BO_ 1620 CAN_Message_1: 8 BCM
 SG_ SIG_12_05 : 55|16@0+ (0.001,0) [0|5] "V"  ECU,BCM
 SG_ SIG_05 : 39|16@0+ (0.001,0) [0|5] "V"  ECU,BCM
 SG_ SIG_05 : 23|16@0+ (0.001,0) [0|5] "V"  ECU,BCM
 SG_ SIG_05 : 7|16@0+ (0.001,0) [0|5] "V"  ECU,BCM

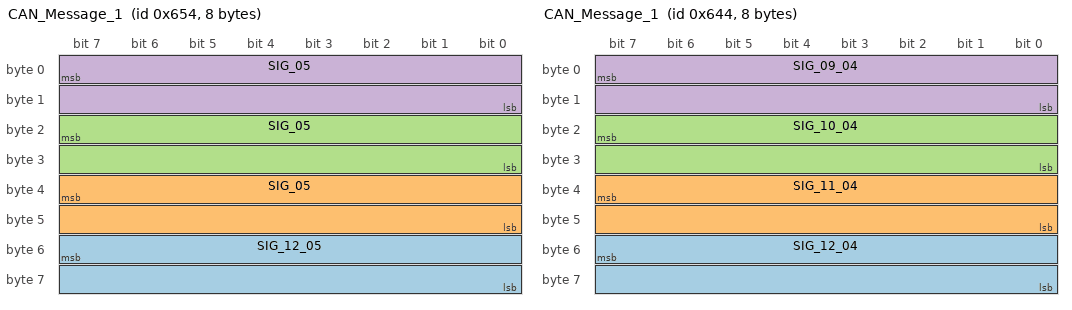
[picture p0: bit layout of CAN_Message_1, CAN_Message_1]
BO_ 1604 CAN_Message_1: 8 BCM
 SG_ SIG_12_04 : 55|16@0+ (0.001,0) [0|5] "V"  ECU,BCM
 SG_ SIG_11_04 : 39|16@0+ (0.001,0) [0|5] "V"  ECU,BCM
 SG_ SIG_10_04 : 23|16@0+ (0.001,0) [0|5] "V"  ECU,BCM
 SG_ SIG_09_04 : 7|16@0+ (0.001,0) [0|5] "V"  ECU,BCM

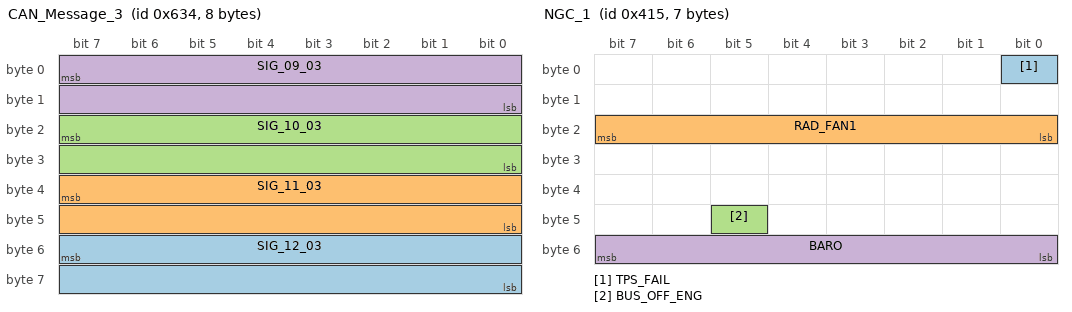
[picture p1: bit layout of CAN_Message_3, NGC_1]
BO_ 1588 CAN_Message_3: 8 BCM
 SG_ SIG_12_03 : 55|16@0+ (0.001,0) [0|5] "V"  ECU,BCM
 SG_ SIG_11_03 : 39|16@0+ (0.001,0) [0|5] "V"  ECU,BCM
 SG_ SIG_10_03 : 23|16@0+ (0.001,0) [0|5] "V"  ECU,BCM
 SG_ SIG_09_03 : 7|16@0+ (0.001,0) [0|5] "V"  ECU,BCM

BO_ 1045 NGC_1: 7 ENG_PHEV
 SG_ TPS_FAIL : 0|1@1+ (1,0) [0|0] ""  TCU,ETACS
 SG_ RAD_FAN1 : 16|8@1+ (1,0) [0|100] "%"  TCU,ETACS,PHEV
 SG_ BUS_OFF_ENG : 45|1@1+ (1,0) [0|0] ""  TCU,ETACS
 SG_ BARO : 48|8@1+ (0.4921875,0) [0|125] "kPa"  TCU,ETACS,PHEV

BO_ 1585 MS_APPL1: 8 ENG_PHEV
 SG_ MS_APPL1 : 7|64@0+ (1,0) [0|0] ""  TESTER

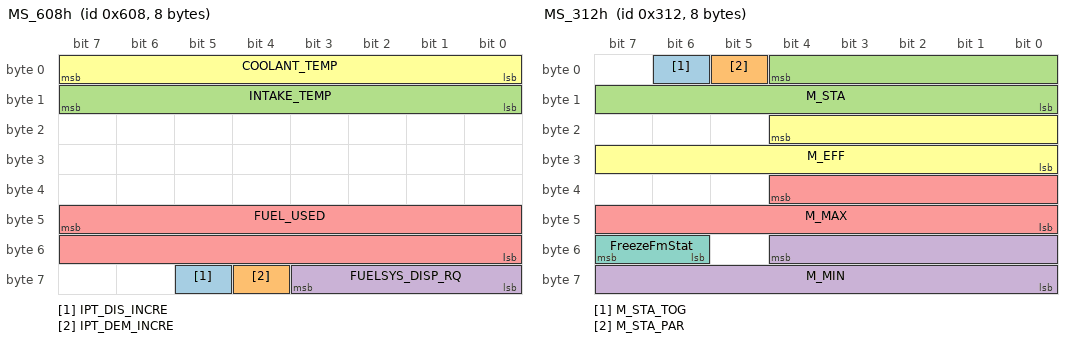
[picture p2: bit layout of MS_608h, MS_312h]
BO_ 1544 MS_608h: 8 ENG_PHEV
 SG_ IPT_DIS_INCRE : 61|1@1+ (1,0) [0|0] ""  TCU,ETACS,PHEV
 SG_ IPT_DEM_INCRE : 60|1@1+ (1,0) [0|0] ""  TCU,ETACS,PHEV
 SG_ INTAKE_TEMP : 8|8@1+ (1,-40) [-40|214] "deg_C"  TCU,ETACS
 SG_ FUELSYS_DISP_RQ : 56|4@1+ (1,0) [0|0] ""  TCU,ETACS
 SG_ FUEL_USED : 47|16@0+ (0.217,0) [0|14220] "uL/100ms"  TCU,ETACS,PHEV
 SG_ COOLANT_TEMP : 0|8@1+ (1,-40) [-40|214] "deg_C"  TCU,ETACS,PHEV

BO_ 786 MS_312h: 8 ENG_PHEV
 SG_ M_STA_TOG : 6|1@1+ (1,0) [0|0] ""  TCU,ABS_ASC
 SG_ M_STA_PAR : 5|1@1+ (1,0) [0|0] ""  TCU,ABS_ASC
 SG_ M_STA : 4|13@0+ (0.25,-500) [-500|1547.5] "Nm"  TCU,PHEV,ABS_ASC
 SG_ M_MIN : 52|13@0+ (0.25,-500) [-500|1547.5] "Nm"  TCU,PHEV,ABS_ASC
 SG_ M_MAX : 36|13@0+ (0.25,-500) [-500|1547.5] "Nm"  TCU,PHEV,ABS_ASC
 SG_ M_EFF : 20|13@0+ (0.25,-500) [-500|1547.5] "Nm"  TCU,ABS_ASC
 SG_ FreezeFmStat : 54|2@1+ (1,0) [0|0] ""  TCU

BA_DEF_DEF_  "fty-HY" 50000.0;

BU_: TESTER TCU BMU2 CSM CMU_TEST CMU_12 CMU_11 CMU_10 CMU_09 CMU_08 CMU_07 CMU_06 CMU_05 CMU_04 CMU_03 CMU_02 CMU_01 CMU_00 BMU
